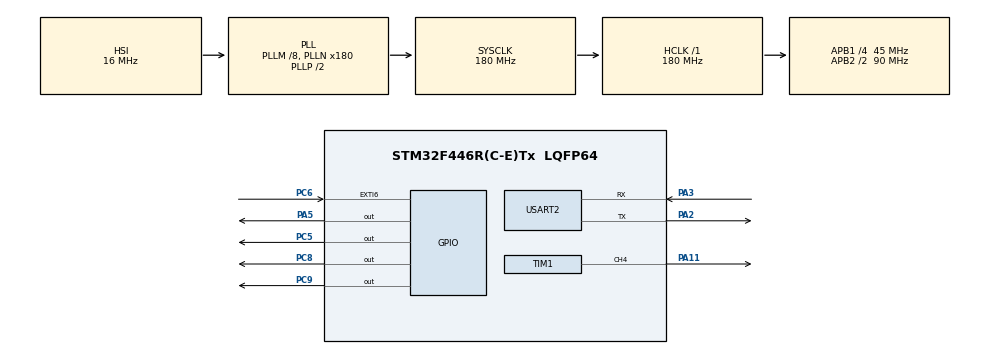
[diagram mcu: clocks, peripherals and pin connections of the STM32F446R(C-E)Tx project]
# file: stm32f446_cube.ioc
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Dma.Request0=USART2_RX
Dma.Request1=USART2_TX
Dma.Request2=TIM1_CH4/TRIG/COM
Dma.Request3=TIM1_CH1
Dma.Request4=TIM1_CH2
Dma.Request5=TIM1_CH3
Dma.TIM1_CH1.3.Direction=DMA_PERIPH_TO_MEMORY
Dma.TIM1_CH1.3.FIFOMode=DMA_FIFOMODE_DISABLE
Dma.TIM1_CH1.3.Instance=DMA2_Stream1
Dma.TIM1_CH1.3.MemDataAlignment=DMA_MDATAALIGN_HALFWORD
Dma.TIM1_CH1.3.MemInc=DMA_MINC_ENABLE
Dma.TIM1_CH1.3.Mode=DMA_NORMAL
Dma.TIM1_CH1.3.PeriphDataAlignment=DMA_PDATAALIGN_HALFWORD
Dma.TIM1_CH1.3.PeriphInc=DMA_PINC_DISABLE
Dma.TIM1_CH1.3.Priority=DMA_PRIORITY_LOW
Dma.TIM1_CH2.4.Direction=DMA_PERIPH_TO_MEMORY
Dma.TIM1_CH2.4.FIFOMode=DMA_FIFOMODE_DISABLE
Dma.TIM1_CH2.4.Instance=DMA2_Stream2
Dma.TIM1_CH2.4.MemDataAlignment=DMA_MDATAALIGN_HALFWORD
Dma.TIM1_CH2.4.MemInc=DMA_MINC_ENABLE
Dma.TIM1_CH2.4.Mode=DMA_NORMAL
Dma.TIM1_CH2.4.PeriphDataAlignment=DMA_PDATAALIGN_HALFWORD
Dma.TIM1_CH2.4.PeriphInc=DMA_PINC_DISABLE
Dma.TIM1_CH2.4.Priority=DMA_PRIORITY_LOW
Dma.TIM1_CH3.5.Direction=DMA_PERIPH_TO_MEMORY
Dma.TIM1_CH3.5.FIFOMode=DMA_FIFOMODE_DISABLE
Dma.TIM1_CH3.5.Instance=DMA2_Stream6
Dma.TIM1_CH3.5.MemDataAlignment=DMA_MDATAALIGN_HALFWORD
Dma.TIM1_CH3.5.MemInc=DMA_MINC_ENABLE
Dma.TIM1_CH3.5.Mode=DMA_NORMAL
Dma.TIM1_CH3.5.PeriphDataAlignment=DMA_PDATAALIGN_HALFWORD
Dma.TIM1_CH3.5.PeriphInc=DMA_PINC_DISABLE
Dma.TIM1_CH3.5.Priority=DMA_PRIORITY_LOW
Dma.TIM1_CH4/TRIG/COM.2.Direction=DMA_PERIPH_TO_MEMORY
Dma.TIM1_CH4/TRIG/COM.2.FIFOMode=DMA_FIFOMODE_DISABLE
Dma.TIM1_CH4/TRIG/COM.2.Instance=DMA2_Stream4
Dma.TIM1_CH4/TRIG/COM.2.MemDataAlignment=DMA_MDATAALIGN_HALFWORD
Dma.TIM1_CH4/TRIG/COM.2.MemInc=DMA_MINC_ENABLE
Dma.TIM1_CH4/TRIG/COM.2.Mode=DMA_NORMAL
Dma.TIM1_CH4/TRIG/COM.2.PeriphDataAlignment=DMA_PDATAALIGN_HALFWORD
Dma.TIM1_CH4/TRIG/COM.2.PeriphInc=DMA_PINC_DISABLE
Dma.TIM1_CH4/TRIG/COM.2.Priority=DMA_PRIORITY_LOW
Dma.USART2_RX.0.Direction=DMA_PERIPH_TO_MEMORY
Dma.USART2_RX.0.FIFOMode=DMA_FIFOMODE_DISABLE
Dma.USART2_RX.0.Instance=DMA1_Stream5
Dma.USART2_RX.0.MemDataAlignment=DMA_MDATAALIGN_BYTE
Dma.USART2_RX.0.MemInc=DMA_MINC_ENABLE
Dma.USART2_RX.0.Mode=DMA_NORMAL
Dma.USART2_RX.0.PeriphDataAlignment=DMA_PDATAALIGN_BYTE
Dma.USART2_RX.0.PeriphInc=DMA_PINC_DISABLE
Dma.USART2_RX.0.Priority=DMA_PRIORITY_LOW
Dma.USART2_TX.1.Direction=DMA_MEMORY_TO_PERIPH
Dma.USART2_TX.1.FIFOMode=DMA_FIFOMODE_DISABLE
Dma.USART2_TX.1.Instance=DMA1_Stream6
Dma.USART2_TX.1.MemDataAlignment=DMA_MDATAALIGN_BYTE
Dma.USART2_TX.1.MemInc=DMA_MINC_ENABLE
Dma.USART2_TX.1.Mode=DMA_NORMAL
Dma.USART2_TX.1.PeriphDataAlignment=DMA_PDATAALIGN_BYTE
Dma.USART2_TX.1.PeriphInc=DMA_PINC_DISABLE
Dma.USART2_TX.1.Priority=DMA_PRIORITY_LOW
Mcu.Family=STM32F4
Mcu.Name=STM32F446R(C-E)Tx
Mcu.Package=LQFP64
NVIC.DMA1_Stream5_IRQn=true\:0\:0\:false\:false\:true\:false\:true\:true
NVIC.DMA1_Stream6_IRQn=true\:0\:0\:false\:false\:true\:false\:true\:true
NVIC.DMA2_Stream1_IRQn=true\:0\:0\:false\:false\:true\:false\:true\:true
NVIC.DMA2_Stream2_IRQn=true\:0\:0\:false\:false\:true\:false\:true\:true
NVIC.DMA2_Stream4_IRQn=true\:0\:0\:false\:false\:true\:false\:true\:true
NVIC.DMA2_Stream6_IRQn=true\:0\:0\:false\:false\:true\:false\:true\:true
NVIC.EXTI9_5_IRQn=true\:0\:0\:false\:false\:true\:true\:true\:true
NVIC.PriorityGroup=NVIC_PRIORITYGROUP_4
NVIC.TIM1_CC_IRQn=true\:0\:0\:false\:false\:true\:true\:true\:true
NVIC.TIM1_UP_TIM10_IRQn=true\:0\:0\:false\:false\:true\:true\:true\:true
NVIC.USART2_IRQn=true\:0\:0\:false\:false\:true\:true\:true\:true
PA11.Signal=S_TIM1_CH4
PA13.Mode=Serial_Wire
PA13.Signal=SYS_JTMS-SWDIO
PA14.Mode=Serial_Wire
PA14.Signal=SYS_JTCK-SWCLK
PA2.Mode=Asynchronous
PA2.Signal=USART2_TX
PA3.Mode=Asynchronous
PA3.Signal=USART2_RX
PA5.Signal=GPIO_Output
PC5.GPIO_Speed=GPIO_SPEED_FREQ_HIGH
PC5.Signal=GPIO_Output
PC6.GPIO_ModeDefaultEXTI=GPIO_MODE_IT_FALLING
PC6.Signal=GPXTI6
PC8.Signal=GPIO_Output
PC9.Signal=GPIO_Output
ProjectManager.HeapSize=0x200
ProjectManager.StackSize=0x400
ProjectManager.TargetToolchain=STM32CubeIDE
RCC.AHBFreq_Value=180000000
RCC.APB1CLKDivider=RCC_HCLK_DIV4
RCC.APB1Freq_Value=45000000
RCC.APB1TimFreq_Value=90000000
RCC.APB2CLKDivider=RCC_HCLK_DIV2
RCC.APB2Freq_Value=90000000
RCC.APB2TimFreq_Value=180000000
RCC.CortexFreq_Value=180000000
RCC.HCLKFreq_Value=180000000
RCC.HSE_VALUE=8000000
RCC.PLLM=8
RCC.PLLN=180
RCC.SYSCLKFreq_VALUE=180000000
RCC.SYSCLKSource=RCC_SYSCLKSOURCE_PLLCLK
RCC.USBFreq_Value=180000000
RCC.VCOOutputFreq_Value=360000000
SH.S_TIM1_CH4.0=TIM1_CH4,Output Compare4 CH4
TIM1.Channel-Output\ Compare1\ No\ Output=TIM_CHANNEL_1
TIM1.Channel-Output\ Compare2\ No\ Output=TIM_CHANNEL_2
TIM1.Channel-Output\ Compare3\ No\ Output=TIM_CHANNEL_3
TIM1.Channel-Output\ Compare4\ CH4=TIM_CHANNEL_4
USART2.VirtualMode=VM_ASYNC
VP_TIM1_VS_ClockSourceINT.Mode=Internal
VP_TIM1_VS_no_output1.Mode=Output Compare1 No Output
VP_TIM1_VS_no_output2.Mode=Output Compare2 No Output
VP_TIM1_VS_no_output3.Mode=Output Compare3 No Output
board=custom

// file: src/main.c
/* USER CODE BEGIN Header */
/**
  ******************************************************************************
  * @file           : main.c
  * @brief          : Main program body
  ******************************************************************************
  * @attention
  *
  * Copyright (c) 2025 STMicroelectronics.
  * All rights reserved.
  *
  * This software is licensed under terms that can be found in the LICENSE file
  * in the root directory of this software component.
  * If no LICENSE file comes with this software, it is provided AS-IS.
  *
  ******************************************************************************
  */
/* USER CODE END Header */
#include "main.h"
#include "dma.h"
#include "tim.h"
#include "usart.h"
#include "gpio.h"
#include "dshot.h"
#include "dshot_bitbang.h"
#include "bb_uart.h"

void SystemClock_Config(void);

/* USER CODE BEGIN 0 */
uint32_t tick1,tick10,tick50,tick100,tick500,tick1000,tick2000,curr_tick;
/* USER CODE END 0 */
dshotProtocolControl_t pcb;
int main(void)
{

  /* MCU Configuration--------------------------------------------------------*/

  /* Reset of all peripherals, Initializes the Flash interface and the Systick. */
  HAL_Init();

  /* Configure the system clock */
  SystemClock_Config();

  /* Initialize all configured peripherals */
  MX_GPIO_Init();
  MX_DMA_Init();
  MX_USART2_UART_Init();
  MX_TIM1_Init();
  /* USER CODE BEGIN 2 */
#ifdef BB_UART
  HAL_GPIO_WritePin(GPIOC,GPIO_PIN_5,GPIO_PIN_SET);
  bb_uart_init(bb_uart_txbuff,GPIO_PIN_5);
  bb_uart_data_set(bb_uart_txbuff,GPIO_PIN_5,'A');
  for(int i=0;i<10*SAMPLERATE;i++)
  {
    printf("%.8lx\r\n",bb_uart_txbuff[i]);
  }
#endif
  /* USER CODE END 2 */
#ifdef USE_DSHOT_BITBANG
  bbOutputDataInit(bbOutputBuffer,GPIO_PIN_5);
  pcb.requestTelemetry=false;
  pcb.value=48;//0x5dc
  uint16_t v=prepareDshotPacket(&pcb);
  bbOutputDataSet(bbOutputBuffer,GPIO_PIN_5,v);
  for(int i=0;i<16;i++){
    printf("%.8lx %.8lx %.8lx\r\n",bbOutputBuffer[0+i*3],bbOutputBuffer[1+i*3],bbOutputBuffer[2+i*3]);
    /*
      1500 -> bb88 -> 1011 1011 1000 1000
      00000020 00000000 00200000
      00000020 00200000 00200000
      00000020 00000000 00200000
      00000020 00000000 00200000
      00000020 00000000 00200000
      00000020 00200000 00200000
      00000020 00000000 00200000
      00000020 00000000 00200000
      00000020 00000000 00200000
      00000020 00200000 00200000
      00000020 00200000 00200000
      00000020 00200000 00200000
      00000020 00000000 00200000
      00000020 00200000 00200000
      00000020 00200000 00200000
      00000020 00200000 00200000
    */
  }
  #endif
  /* Infinite loop */
  /* USER CODE BEGIN WHILE */
  tick1=tick10=tick50=tick100=tick500=tick1000=tick2000=curr_tick=HAL_GetTick();
  //HAL_TIM_OC_Start_IT(&htim1,TIM_CHANNEL_4);
  HAL_UARTEx_ReceiveToIdle_DMA(&huart2,rxbuff,0xffff);
  hdma_tim1_ch1.XferCpltCallback=tim1_dma_callback;
  hdma_tim1_ch2.XferCpltCallback=tim1_ch2_dma_callback;
  __HAL_TIM_ENABLE(&htim1);
  while (1)
  {
    /* USER CODE END WHILE */
    if(curr_tick-tick1>=1){
      tick1=curr_tick;
#ifdef USE_DSHOT_BITBANG
       if(rx_flag)
      {
       rx_flag=false;
       pcb.value=atoi(rxbuff);//
        printf("uart get %d\r\n",pcb.value);
        uint16_t v=prepareDshotPacket(&pcb);
        bbOutputDataClear(bbOutputBuffer);
        bbOutputDataSet(bbOutputBuffer,GPIO_PIN_5,v);
      }
     // printf("tim sr before %x %x\r\n",TIM1->SR,TIM1->CCER);
     // __HAL_TIM_CLEAR_FLAG(&htim1,TIM_FLAG_CC1);
     // printf("tim sr after %x\r\n",TIM1->SR);
      //TIM1->EGR|=1;

       HAL_DMA_Start_IT(&hdma_tim1_ch1,(uint32_t)bbOutputBuffer,(uint32_t)&GPIOC->BSRR,48);
      __HAL_TIM_ENABLE_DMA(&htim1, TIM_DMA_CC1);
       //__HAL_TIM_CLEAR_FLAG(&htim1,TIM_FLAG_CC1);
#endif
    }
    if(curr_tick-tick10>=10){
      tick10=curr_tick;
    }
    if(curr_tick-tick50>=50){
      tick50=curr_tick;
    }
    if(curr_tick-tick100>=100){
      tick100=curr_tick;
    }
    if(curr_tick-tick500>=500){
      tick500=curr_tick;
     // printf("test\r\n");
      HAL_GPIO_TogglePin(GPIOA,GPIO_PIN_5);  //heartbeat
    }
    if(curr_tick-tick1000>=1000){
      tick1000=curr_tick;
#ifdef BB_UART
      if(rx_flag)
      {
        rx_flag=false;
        bb_uart_data_clear(bb_uart_txbuff,GPIO_PIN_5);
        bb_uart_data_set(bb_uart_txbuff,GPIO_PIN_5,rxbuff[0]);
      }

      extern uint8_t rx[10],rcnt;
      if(rcnt){
        for(int i=0;i<rcnt;i++){
            bb_uart_data_clear(bb_uart_txbuff,GPIO_PIN_5);
            bb_uart_data_set(bb_uart_txbuff,GPIO_PIN_5,rx[i]);
            bb_uart_tx();
            HAL_Delay(1);
        }
        rcnt=0;
      }

#endif
    }
    if(curr_tick-tick2000>=2000){
      tick2000=curr_tick;
    }
    curr_tick=HAL_GetTick();
  }
}

void SystemClock_Config(void)
{
  RCC_OscInitTypeDef RCC_OscInitStruct = {0};
  RCC_ClkInitTypeDef RCC_ClkInitStruct = {0};

  /** Configure the main internal regulator output voltage
  */
  __HAL_RCC_PWR_CLK_ENABLE();
  __HAL_PWR_VOLTAGESCALING_CONFIG(PWR_REGULATOR_VOLTAGE_SCALE1);

  /** Initializes the RCC Oscillators according to the specified parameters
  * in the RCC_OscInitTypeDef structure.
  */
  RCC_OscInitStruct.OscillatorType = RCC_OSCILLATORTYPE_HSI;
  RCC_OscInitStruct.HSIState = RCC_HSI_ON;
  RCC_OscInitStruct.HSICalibrationValue = RCC_HSICALIBRATION_DEFAULT;
  RCC_OscInitStruct.PLL.PLLState = RCC_PLL_ON;
  RCC_OscInitStruct.PLL.PLLSource = RCC_PLLSOURCE_HSI;
  RCC_OscInitStruct.PLL.PLLM = 8;
  RCC_OscInitStruct.PLL.PLLN = 180;
  RCC_OscInitStruct.PLL.PLLP = RCC_PLLP_DIV2;
  RCC_OscInitStruct.PLL.PLLQ = 2;
  RCC_OscInitStruct.PLL.PLLR = 2;
  if (HAL_RCC_OscConfig(&RCC_OscInitStruct) != HAL_OK)
  {
    Error_Handler();
  }

  /** Activate the Over-Drive mode
  */
  if (HAL_PWREx_EnableOverDrive() != HAL_OK)
  {
    Error_Handler();
  }

  /** Initializes the CPU, AHB and APB buses clocks
  */
  RCC_ClkInitStruct.ClockType = RCC_CLOCKTYPE_HCLK|RCC_CLOCKTYPE_SYSCLK
                              |RCC_CLOCKTYPE_PCLK1|RCC_CLOCKTYPE_PCLK2;
  RCC_ClkInitStruct.SYSCLKSource = RCC_SYSCLKSOURCE_PLLCLK;
  RCC_ClkInitStruct.AHBCLKDivider = RCC_SYSCLK_DIV1;
  RCC_ClkInitStruct.APB1CLKDivider = RCC_HCLK_DIV4;
  RCC_ClkInitStruct.APB2CLKDivider = RCC_HCLK_DIV2;

  if (HAL_RCC_ClockConfig(&RCC_ClkInitStruct, FLASH_LATENCY_5) != HAL_OK)
  {
    Error_Handler();
  }
}

void Error_Handler(void)
{
  __disable_irq();
  while (1)
  {
  }
}
